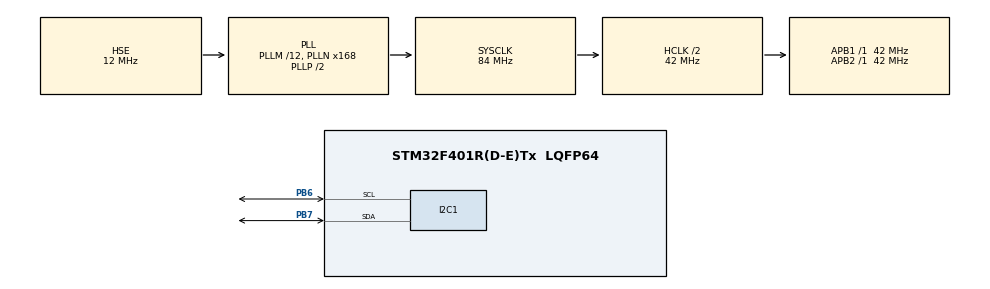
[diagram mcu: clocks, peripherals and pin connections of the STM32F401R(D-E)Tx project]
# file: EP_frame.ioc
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Mcu.Family=STM32F4
Mcu.Name=STM32F401R(D-E)Tx
Mcu.Package=LQFP64
NVIC.PriorityGroup=NVIC_PRIORITYGROUP_4
NVIC.TIM1_UP_TIM10_IRQn=true\:0\:0\:false\:false\:true\:true\:true
PB6.Mode=I2C
PB6.Signal=I2C1_SCL
PB7.Mode=I2C
PB7.Signal=I2C1_SDA
PH0\ -\ OSC_IN.Mode=HSE-External-Oscillator
PH0\ -\ OSC_IN.Signal=RCC_OSC_IN
PH1\ -\ OSC_OUT.Mode=HSE-External-Oscillator
PH1\ -\ OSC_OUT.Signal=RCC_OSC_OUT
ProjectManager.HeapSize=0x2000
ProjectManager.StackSize=0x4000
ProjectManager.TargetToolchain=MDK-ARM V5
RCC.48MHZClocksFreq_Value=42000000
RCC.AHBCLKDivider=RCC_SYSCLK_DIV2
RCC.AHBFreq_Value=42000000
RCC.APB1Freq_Value=42000000
RCC.APB1TimFreq_Value=42000000
RCC.APB2Freq_Value=42000000
RCC.APB2TimFreq_Value=42000000
RCC.CortexFreq_Value=42000000
RCC.HCLKFreq_Value=42000000
RCC.HSE_VALUE=12000000
RCC.HSI_VALUE=16000000
RCC.LSE_VALUE=32768
RCC.PLLM=12
RCC.PLLN=168
RCC.PLLSourceVirtual=RCC_PLLSOURCE_HSE
RCC.SYSCLKFreq_VALUE=84000000
RCC.SYSCLKSource=RCC_SYSCLKSOURCE_PLLCLK
RCC.VCOOutputFreq_Value=168000000
TIM10.Period=1000
TIM10.Prescaler=42-1
VP_TIM10_VS_ClockSourceINT.Mode=Enable_Timer
board=custom

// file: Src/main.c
/* USER CODE BEGIN Header */
/**
  ******************************************************************************
  * @file           : main.c
  * @brief          : Main program body
  ******************************************************************************
  * @attention
  *
  * <h2><center>&copy; Copyright (c) 2021 STMicroelectronics.
  * All rights reserved.</center></h2>
  *
  * This software component is licensed by ST under BSD 3-Clause license,
  * the "License"; You may not use this file except in compliance with the
  * License. You may obtain a copy of the License at:
  *                        opensource.org/licenses/BSD-3-Clause
  *
  ******************************************************************************
  */
/* USER CODE END Header */

#include "main.h"
#include "i2c.h"
#include "tim.h"
#include "gpio.h"
#include "stm32f4xx_hal.h"

/* USER CODE BEGIN Includes */
#include "include.h"
/* USER CODE END Includes */

void SystemClock_Config(void);

int main(void)
{

  /* MCU Configuration--------------------------------------------------------*/

  /* Reset of all peripherals, Initializes the Flash interface and the Systick. */
  HAL_Init();

  /* Configure the system clock */
  SystemClock_Config();

  /* USER CODE BEGIN SysInit */
  HAL_NVIC_DisableIRQ(TIM1_UP_TIM10_IRQn);
  /* USER CODE END SysInit */

  /* Initialize all configured peripherals */
  MX_GPIO_Init();
  MX_I2C1_Init();
  MX_TIM10_Init();
  /* USER CODE BEGIN 2 */
  HAL_TIM_Base_Start_IT(&htim10);

  HAL_NVIC_EnableIRQ(TIM1_UP_TIM10_IRQn);
  /* USER CODE END 2 */

  /* Infinite loop */
  while (1)
  {

  }
}

void SystemClock_Config(void)
{
  RCC_OscInitTypeDef RCC_OscInitStruct = {0};
  RCC_ClkInitTypeDef RCC_ClkInitStruct = {0};

  /** Configure the main internal regulator output voltage
  */
  __HAL_RCC_PWR_CLK_ENABLE();
  __HAL_PWR_VOLTAGESCALING_CONFIG(PWR_REGULATOR_VOLTAGE_SCALE2);
  /** Initializes the CPU, AHB and APB busses clocks
  */
  RCC_OscInitStruct.OscillatorType = RCC_OSCILLATORTYPE_HSE;
  RCC_OscInitStruct.HSEState = RCC_HSE_ON;
  RCC_OscInitStruct.PLL.PLLState = RCC_PLL_ON;
  RCC_OscInitStruct.PLL.PLLSource = RCC_PLLSOURCE_HSE;
  RCC_OscInitStruct.PLL.PLLM = 12;
  RCC_OscInitStruct.PLL.PLLN = 168;
  RCC_OscInitStruct.PLL.PLLP = RCC_PLLP_DIV2;
  RCC_OscInitStruct.PLL.PLLQ = 4;
  if (HAL_RCC_OscConfig(&RCC_OscInitStruct) != HAL_OK)
  {
    Error_Handler();
  }
  /** Initializes the CPU, AHB and APB busses clocks
  */
  RCC_ClkInitStruct.ClockType = RCC_CLOCKTYPE_HCLK|RCC_CLOCKTYPE_SYSCLK
                              |RCC_CLOCKTYPE_PCLK1|RCC_CLOCKTYPE_PCLK2;
  RCC_ClkInitStruct.SYSCLKSource = RCC_SYSCLKSOURCE_PLLCLK;
  RCC_ClkInitStruct.AHBCLKDivider = RCC_SYSCLK_DIV2;
  RCC_ClkInitStruct.APB1CLKDivider = RCC_HCLK_DIV1;
  RCC_ClkInitStruct.APB2CLKDivider = RCC_HCLK_DIV1;

  if (HAL_RCC_ClockConfig(&RCC_ClkInitStruct, FLASH_LATENCY_1) != HAL_OK)
  {
    Error_Handler();
  }
}

void Error_Handler(void)
{
}

/************************ (C) COPYRIGHT STMicroelectronics *****END OF FILE****/
